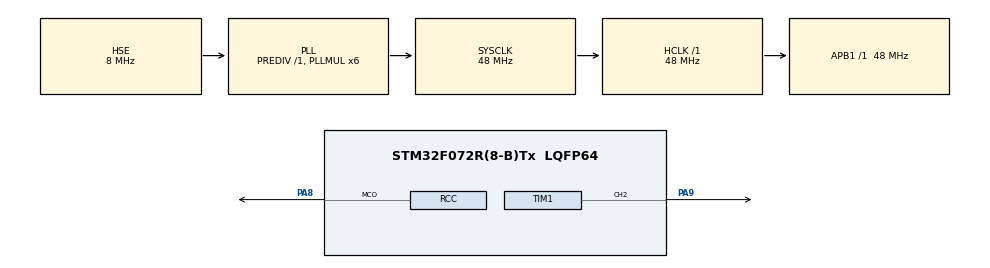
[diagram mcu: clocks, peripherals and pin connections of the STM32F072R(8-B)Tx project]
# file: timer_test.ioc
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Mcu.Family=STM32F0
Mcu.Name=STM32F072R(8-B)Tx
Mcu.Package=LQFP64
NVIC.TIM2_IRQn=true\:0\:0\:false\:false\:true\:true
PA8.Mode=Clock-out
PA8.Signal=RCC_MCO
PA9.Signal=S_TIM1_CH2
PF0-OSC_IN.Mode=HSE-External-Oscillator
PF0-OSC_IN.Signal=RCC_OSC_IN
PF1-OSC_OUT.Mode=HSE-External-Oscillator
PF1-OSC_OUT.Signal=RCC_OSC_OUT
ProjectManager.HeapSize=0x200
ProjectManager.StackSize=0x400
ProjectManager.TargetToolchain=MDK-ARM V5
RCC.AHBFreq_Value=48000000
RCC.APB1Freq_Value=48000000
RCC.APB1TimFreq_Value=48000000
RCC.HCLKFreq_Value=48000000
RCC.PLLMUL=RCC_PLL_MUL6
RCC.PLLSourceVirtual=RCC_PLLSOURCE_HSE
RCC.RCC_MCODiv=RCC_MCODIV_8
RCC.RCC_MCOSource=RCC_MCO1SOURCE_PLLCLK
RCC.SYSCLKFreq_VALUE=48000000
RCC.SYSCLKSource=RCC_SYSCLKSOURCE_PLLCLK
SH.S_TIM1_CH2.0=TIM1_CH2,PWM Generation2 CH2
TIM1.Channel-PWM\ Generation2\ CH2=TIM_CHANNEL_2
TIM1.OCFastMode_PWM-PWM\ Generation2\ CH2=TIM_OCFAST_ENABLE
TIM1.Period=2
TIM1.Prescaler=47
TIM1.Pulse-PWM\ Generation2\ CH2=1
TIM2.CounterMode=TIM_COUNTERMODE_DOWN
TIM2.Period=30
TIM2.Prescaler=47
TIM2.TIM_MasterOutputTrigger=TIM_TRGO_ENABLE
TIM2.TIM_MasterSlaveMode=TIM_MASTERSLAVEMODE_DISABLE
VP_TIM1_VS_ClockSourceINT.Mode=Internal
VP_TIM1_VS_ClockSourceITR.Mode=TriggerSource_ITR1
VP_TIM1_VS_ControllerModeGated.Mode=Gated Mode
VP_TIM2_VS_ClockSourceINT.Mode=Internal
board=custom

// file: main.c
/**
  ******************************************************************************
  * @file           : main.c
  * @brief          : Main program body
  ******************************************************************************
  ** This notice applies to any and all portions of this file
  * that are not between comment pairs USER CODE BEGIN and
  * USER CODE END. Other portions of this file, whether
  * inserted by the user or by software development tools
  * are owned by their respective copyright owners.
  *
  * COPYRIGHT(c) 2018 STMicroelectronics
  *
  * Redistribution and use in source and binary forms, with or without modification,
  * are permitted provided that the following conditions are met:
  *   1. Redistributions of source code must retain the above copyright notice,
  *      this list of conditions and the following disclaimer.
  *   2. Redistributions in binary form must reproduce the above copyright notice,
  *      this list of conditions and the following disclaimer in the documentation
  *      and/or other materials provided with the distribution.
  *   3. Neither the name of STMicroelectronics nor the names of its contributors
  *      may be used to endorse or promote products derived from this software
  *      without specific prior written permission.
  *
  * THIS SOFTWARE IS PROVIDED BY THE COPYRIGHT HOLDERS AND CONTRIBUTORS "AS IS"
  * AND ANY EXPRESS OR IMPLIED WARRANTIES, INCLUDING, BUT NOT LIMITED TO, THE
  * IMPLIED WARRANTIES OF MERCHANTABILITY AND FITNESS FOR A PARTICULAR PURPOSE ARE
  * DISCLAIMED. IN NO EVENT SHALL THE COPYRIGHT HOLDER OR CONTRIBUTORS BE LIABLE
  * FOR ANY DIRECT, INDIRECT, INCIDENTAL, SPECIAL, EXEMPLARY, OR CONSEQUENTIAL
  * DAMAGES (INCLUDING, BUT NOT LIMITED TO, PROCUREMENT OF SUBSTITUTE GOODS OR
  * SERVICES; LOSS OF USE, DATA, OR PROFITS; OR BUSINESS INTERRUPTION) HOWEVER
  * CAUSED AND ON ANY THEORY OF LIABILITY, WHETHER IN CONTRACT, STRICT LIABILITY,
  * OR TORT (INCLUDING NEGLIGENCE OR OTHERWISE) ARISING IN ANY WAY OUT OF THE USE
  * OF THIS SOFTWARE, EVEN IF ADVISED OF THE POSSIBILITY OF SUCH DAMAGE.
  *
  ******************************************************************************
  */
#include "main.h"
#include "stm32f0xx_hal.h"

TIM_HandleTypeDef htim1;
TIM_HandleTypeDef htim2;

/* USER CODE BEGIN PV */
/* Private variables ---------------------------------------------------------*/
#define SYS_REFERENCE_FREQ 48000000L
#define PWM_REFERENCE_FREQ 2000000L
#define PWM_PULSE_FREQ 400000L

static uint16_t PULSE_COUNT = 10;
static uint16_t pwm_period = (uint16_t)(PWM_REFERENCE_FREQ / PWM_PULSE_FREQ - 1);
static uint16_t pwm_prescaler = (uint16_t)(SYS_REFERENCE_FREQ / PWM_REFERENCE_FREQ - 1);
static uint16_t trg_prescaler = (uint16_t)(SYS_REFERENCE_FREQ / PWM_PULSE_FREQ - 1);

bool volatile ready = true;

/* USER CODE END PV */

void SystemClock_Config(void);
static void MX_GPIO_Init(void);
static void MX_TIM1_Init(void);
static void MX_TIM2_Init(void);
void HAL_TIM_MspPostInit(TIM_HandleTypeDef *htim);

/* USER CODE BEGIN PFP */
/* Private function prototypes -----------------------------------------------*/
void HAL_TIM_PeriodElapsedCallback(TIM_HandleTypeDef *htim) {
    htim->Instance->CR1 &= ~ TIM_CR1_CEN;
    ready = true;
}
/* USER CODE END PFP */

int main(void)
{

  /* MCU Configuration----------------------------------------------------------*/

  /* Reset of all peripherals, Initializes the Flash interface and the Systick. */
  HAL_Init();

  /* Configure the system clock */
  SystemClock_Config();

  /* Initialize all configured peripherals */
  MX_GPIO_Init();
  MX_TIM1_Init();
  MX_TIM2_Init();
  /* USER CODE BEGIN 2 */
  TIM2->CR1 &= ~TIM_CR1_CEN;

  TIM_CCxChannelCmd(TIM1, TIM_CHANNEL_2, TIM_CCx_ENABLE);
__HAL_TIM_MOE_ENABLE(&htim1);
__HAL_TIM_ENABLE(&htim1);
      __HAL_TIM_ENABLE_IT(&htim2, TIM_IT_UPDATE);

  /* USER CODE END 2 */

  /* Infinite loop */
  while (1)
  {
  /* USER CODE BEGIN 3 */
      while (!ready);
      ready = false;
      HAL_Delay(100);
      TIM2->ARR = PULSE_COUNT++;
      //__HAL_TIM_ENABLE_IT(&htim2, TIM_IT_UPDATE);
      TIM2->CR1 |= TIM_CR1_CEN;

  }
  /* USER CODE END 3 */

}

void SystemClock_Config(void)
{

  RCC_OscInitTypeDef RCC_OscInitStruct;
  RCC_ClkInitTypeDef RCC_ClkInitStruct;

    /**Initializes the CPU, AHB and APB busses clocks
    */
  RCC_OscInitStruct.OscillatorType = RCC_OSCILLATORTYPE_HSE;
  RCC_OscInitStruct.HSEState = RCC_HSE_ON;
  RCC_OscInitStruct.PLL.PLLState = RCC_PLL_ON;
  RCC_OscInitStruct.PLL.PLLSource = RCC_PLLSOURCE_HSE;
  RCC_OscInitStruct.PLL.PLLMUL = RCC_PLL_MUL6;
  RCC_OscInitStruct.PLL.PREDIV = RCC_PREDIV_DIV1;
  if (HAL_RCC_OscConfig(&RCC_OscInitStruct) != HAL_OK)
  {
    _Error_Handler(__FILE__, __LINE__);
  }

    /**Initializes the CPU, AHB and APB busses clocks
    */
  RCC_ClkInitStruct.ClockType = RCC_CLOCKTYPE_HCLK|RCC_CLOCKTYPE_SYSCLK
                              |RCC_CLOCKTYPE_PCLK1;
  RCC_ClkInitStruct.SYSCLKSource = RCC_SYSCLKSOURCE_PLLCLK;
  RCC_ClkInitStruct.AHBCLKDivider = RCC_SYSCLK_DIV1;
  RCC_ClkInitStruct.APB1CLKDivider = RCC_HCLK_DIV1;

  if (HAL_RCC_ClockConfig(&RCC_ClkInitStruct, FLASH_LATENCY_1) != HAL_OK)
  {
    _Error_Handler(__FILE__, __LINE__);
  }

  HAL_RCC_MCOConfig(RCC_MCO, RCC_MCO1SOURCE_PLLCLK, RCC_MCODIV_8);

    /**Configure the Systick interrupt time
    */
  HAL_SYSTICK_Config(HAL_RCC_GetHCLKFreq()/1000);

    /**Configure the Systick
    */
  HAL_SYSTICK_CLKSourceConfig(SYSTICK_CLKSOURCE_HCLK);

  /* SysTick_IRQn interrupt configuration */
  HAL_NVIC_SetPriority(SysTick_IRQn, 0, 0);
}

/* TIM1 init function */
static void MX_TIM1_Init(void)
{

  TIM_ClockConfigTypeDef sClockSourceConfig;
  TIM_SlaveConfigTypeDef sSlaveConfig;
  TIM_MasterConfigTypeDef sMasterConfig;
  TIM_OC_InitTypeDef sConfigOC;
  TIM_BreakDeadTimeConfigTypeDef sBreakDeadTimeConfig;

  htim1.Instance = TIM1;
  htim1.Init.Prescaler = pwm_prescaler;
  htim1.Init.CounterMode = TIM_COUNTERMODE_UP;
  htim1.Init.Period = pwm_period;
  htim1.Init.ClockDivision = TIM_CLOCKDIVISION_DIV1;
  htim1.Init.RepetitionCounter = 0;
  htim1.Init.AutoReloadPreload = TIM_AUTORELOAD_PRELOAD_DISABLE;
  if (HAL_TIM_Base_Init(&htim1) != HAL_OK)
  {
    _Error_Handler(__FILE__, __LINE__);
  }

  sClockSourceConfig.ClockSource = TIM_CLOCKSOURCE_INTERNAL;
  if (HAL_TIM_ConfigClockSource(&htim1, &sClockSourceConfig) != HAL_OK)
  {
    _Error_Handler(__FILE__, __LINE__);
  }

  if (HAL_TIM_PWM_Init(&htim1) != HAL_OK)
  {
    _Error_Handler(__FILE__, __LINE__);
  }

  sSlaveConfig.SlaveMode = TIM_SLAVEMODE_GATED;
  sSlaveConfig.InputTrigger = TIM_TS_ITR1;
  if (HAL_TIM_SlaveConfigSynchronization(&htim1, &sSlaveConfig) != HAL_OK)
  {
    _Error_Handler(__FILE__, __LINE__);
  }

  sMasterConfig.MasterOutputTrigger = TIM_TRGO_RESET;
  sMasterConfig.MasterSlaveMode = TIM_MASTERSLAVEMODE_DISABLE;
  if (HAL_TIMEx_MasterConfigSynchronization(&htim1, &sMasterConfig) != HAL_OK)
  {
    _Error_Handler(__FILE__, __LINE__);
  }

  sConfigOC.OCMode = TIM_OCMODE_PWM1;
  sConfigOC.Pulse = pwm_period / 2;
  sConfigOC.OCPolarity = TIM_OCPOLARITY_LOW;
  sConfigOC.OCNPolarity = TIM_OCNPOLARITY_HIGH;
  sConfigOC.OCFastMode = TIM_OCFAST_ENABLE;
  sConfigOC.OCIdleState = TIM_OCIDLESTATE_RESET;
  sConfigOC.OCNIdleState = TIM_OCNIDLESTATE_RESET;
  if (HAL_TIM_PWM_ConfigChannel(&htim1, &sConfigOC, TIM_CHANNEL_2) != HAL_OK)
  {
    _Error_Handler(__FILE__, __LINE__);
  }

  sBreakDeadTimeConfig.OffStateRunMode = TIM_OSSR_DISABLE;
  sBreakDeadTimeConfig.OffStateIDLEMode = TIM_OSSI_DISABLE;
  sBreakDeadTimeConfig.LockLevel = TIM_LOCKLEVEL_OFF;
  sBreakDeadTimeConfig.DeadTime = 0;
  sBreakDeadTimeConfig.BreakState = TIM_BREAK_DISABLE;
  sBreakDeadTimeConfig.BreakPolarity = TIM_BREAKPOLARITY_HIGH;
  sBreakDeadTimeConfig.AutomaticOutput = TIM_AUTOMATICOUTPUT_DISABLE;
  if (HAL_TIMEx_ConfigBreakDeadTime(&htim1, &sBreakDeadTimeConfig) != HAL_OK)
  {
    _Error_Handler(__FILE__, __LINE__);
  }

  HAL_TIM_MspPostInit(&htim1);

}

/* TIM2 init function */
static void MX_TIM2_Init(void)
{

  TIM_ClockConfigTypeDef sClockSourceConfig;
  TIM_MasterConfigTypeDef sMasterConfig;

  htim2.Instance = TIM2;
  htim2.Init.Prescaler = trg_prescaler;
  htim2.Init.CounterMode = TIM_COUNTERMODE_DOWN;
  htim2.Init.Period = 0;
  htim2.Init.ClockDivision = TIM_CLOCKDIVISION_DIV1;
  htim2.Init.AutoReloadPreload = TIM_AUTORELOAD_PRELOAD_DISABLE;
  if (HAL_TIM_Base_Init(&htim2) != HAL_OK)
  {
    _Error_Handler(__FILE__, __LINE__);
  }

  sClockSourceConfig.ClockSource = TIM_CLOCKSOURCE_INTERNAL;
  if (HAL_TIM_ConfigClockSource(&htim2, &sClockSourceConfig) != HAL_OK)
  {
    _Error_Handler(__FILE__, __LINE__);
  }

  sMasterConfig.MasterOutputTrigger = TIM_TRGO_ENABLE;
  sMasterConfig.MasterSlaveMode = TIM_MASTERSLAVEMODE_ENABLE;
  if (HAL_TIMEx_MasterConfigSynchronization(&htim2, &sMasterConfig) != HAL_OK)
  {
    _Error_Handler(__FILE__, __LINE__);
  }

}

/** Configure pins as
        * Analog
        * Input
        * Output
        * EVENT_OUT
        * EXTI
     PA8   ------> RCC_MCO
*/
static void MX_GPIO_Init(void)
{

  GPIO_InitTypeDef GPIO_InitStruct;

  /* GPIO Ports Clock Enable */
  __HAL_RCC_GPIOF_CLK_ENABLE();
  __HAL_RCC_GPIOA_CLK_ENABLE();

  /*Configure GPIO pin : PA8 */
  GPIO_InitStruct.Pin = GPIO_PIN_8;
  GPIO_InitStruct.Mode = GPIO_MODE_AF_PP;
  GPIO_InitStruct.Pull = GPIO_NOPULL;
  GPIO_InitStruct.Speed = GPIO_SPEED_FREQ_LOW;
  GPIO_InitStruct.Alternate = GPIO_AF0_MCO;
  HAL_GPIO_Init(GPIOA, &GPIO_InitStruct);

}

void _Error_Handler(char *file, int line)
{
  while(1)
  {
  }
}

/************************ (C) COPYRIGHT STMicroelectronics *****END OF FILE****/
